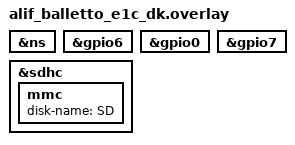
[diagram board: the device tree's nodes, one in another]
/*
 * Copyright (c) 2025 Alif Semiconductor.
 * SPDX-License-Identifier: Apache-2.0
 */

ns: &ns {
	status = "okay";
};

/* GPIO6 is needed for SDHC card-detect */
&gpio6 {
	status = "okay";
};

/* GPIO0 is needed for SDHC sd-vsel regulator */
&gpio0 {
	status = "okay";
};

/* GPIO7 is needed for SDHC sd-pwr regulator */
&gpio7 {
	status = "okay";
};

sdhc: &sdhc {
	status = "okay";

	mmc {
		status = "okay";
		disk-name = "SD";
	};
};
